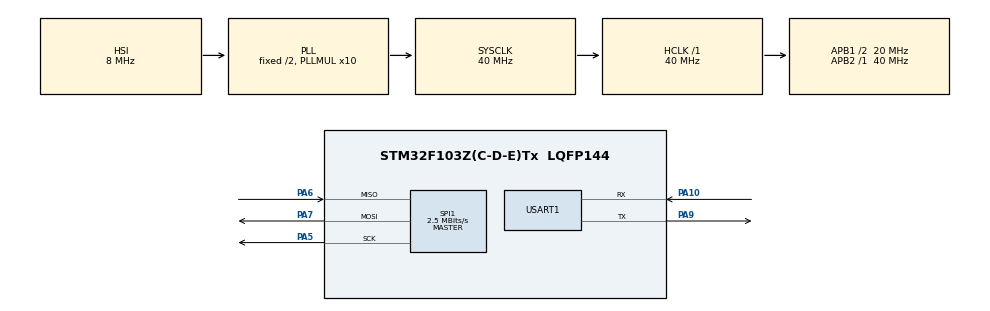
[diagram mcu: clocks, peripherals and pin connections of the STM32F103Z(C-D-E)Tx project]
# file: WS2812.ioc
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Mcu.Family=STM32F1
Mcu.Name=STM32F103Z(C-D-E)Tx
Mcu.Package=LQFP144
NVIC.PriorityGroup=NVIC_PRIORITYGROUP_4
OSC_IN.Mode=HSE-External-Oscillator
OSC_IN.Signal=RCC_OSC_IN
OSC_OUT.Mode=HSE-External-Oscillator
OSC_OUT.Signal=RCC_OSC_OUT
PA10.Mode=Asynchronous
PA10.Signal=USART1_RX
PA13.Mode=Serial_Wire
PA13.Signal=SYS_JTMS-SWDIO
PA14.Mode=Serial_Wire
PA14.Signal=SYS_JTCK-SWCLK
PA5.Mode=Full_Duplex_Master
PA5.Signal=SPI1_SCK
PA6.Mode=Full_Duplex_Master
PA6.Signal=SPI1_MISO
PA7.Mode=Full_Duplex_Master
PA7.Signal=SPI1_MOSI
PA9.Mode=Asynchronous
PA9.Signal=USART1_TX
PC14-OSC32_IN.Mode=LSE-External-Oscillator
PC14-OSC32_IN.Signal=RCC_OSC32_IN
PC15-OSC32_OUT.Mode=LSE-External-Oscillator
PC15-OSC32_OUT.Signal=RCC_OSC32_OUT
ProjectManager.HeapSize=0x200
ProjectManager.StackSize=0x400
ProjectManager.TargetToolchain=MDK-ARM V5.27
RCC.AHBFreq_Value=40000000
RCC.APB1CLKDivider=RCC_HCLK_DIV2
RCC.APB1Freq_Value=20000000
RCC.APB1TimFreq_Value=40000000
RCC.APB2Freq_Value=40000000
RCC.APB2TimFreq_Value=40000000
RCC.HCLKFreq_Value=40000000
RCC.PLLMUL=RCC_PLL_MUL10
RCC.SYSCLKFreq_VALUE=40000000
RCC.SYSCLKSource=RCC_SYSCLKSOURCE_PLLCLK
RCC.USBFreq_Value=40000000
SPI1.BaudRatePrescaler=SPI_BAUDRATEPRESCALER_16
SPI1.CalculateBaudRate=2.5 MBits/s
SPI1.Direction=SPI_DIRECTION_2LINES
SPI1.Mode=SPI_MODE_MASTER
SPI1.VirtualType=VM_MASTER
USART1.VirtualMode=VM_ASYNC
board=custom

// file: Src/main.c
/* USER CODE BEGIN Header */
/**
  ******************************************************************************
  * @file           : main.c
  * @brief          : Main program body
  ******************************************************************************
  * @attention
  *
  * <h2><center>&copy; Copyright (c) 2019 STMicroelectronics.
  * All rights reserved.</center></h2>
  *
  * This software component is licensed by ST under BSD 3-Clause license,
  * the "License"; You may not use this file except in compliance with the
  * License. You may obtain a copy of the License at:
  *                        opensource.org/licenses/BSD-3-Clause
  *
  ******************************************************************************
  */
/* USER CODE END Header */

#include "main.h"
#include "spi.h"
#include "usart.h"
#include "gpio.h"

/* USER CODE BEGIN Includes */
#include "WS2812.h"
/* USER CODE END Includes */

void SystemClock_Config(void);

int main(void)
{

  /* MCU Configuration--------------------------------------------------------*/

  /* Reset of all peripherals, Initializes the Flash interface and the Systick. */
  HAL_Init();

  /* Configure the system clock */
  SystemClock_Config();

  /* Initialize all configured peripherals */
  MX_GPIO_Init();
  MX_SPI1_Init();
  MX_USART1_UART_Init();
  /* USER CODE BEGIN 2 */
	WS2812_Init();
	WS2812_send_data();
	uint8_t R = 0, G = 0, B = 0;
	uint32_t color = 0;
  /* USER CODE END 2 */

  /* Infinite loop */
  /* USER CODE BEGIN WHILE */
  while (1)
  {
//		for(int i = 0; i< 256; i++){
//			G=i;R=i;B=i;
//			WS2812_data9X8bit_data(i,G, R, B);
//		}
//		WS2812_data9X8bit_data(1,255, 0, 0);
//		WS2812_data9X8bit_data(2,0, 255, 0);
//		WS2812_data9X8bit_data(3,255, 255, 255);
		for( int i = 0; i < 1677215; i++){
			WS2812_data9X8bit_data(1,i / 256 / 256 % 256, i / 256 % 256, i%256);
			WS2812_send_data();
			printf("\r\n--%d--",i);
			HAL_Delay(1);
		}

    /* USER CODE END WHILE */

  }
}

void SystemClock_Config(void)
{
  RCC_OscInitTypeDef RCC_OscInitStruct = {0};
  RCC_ClkInitTypeDef RCC_ClkInitStruct = {0};

  /** Initializes the CPU, AHB and APB busses clocks
  */
  RCC_OscInitStruct.OscillatorType = RCC_OSCILLATORTYPE_HSI;
  RCC_OscInitStruct.HSIState = RCC_HSI_ON;
  RCC_OscInitStruct.HSICalibrationValue = RCC_HSICALIBRATION_DEFAULT;
  RCC_OscInitStruct.PLL.PLLState = RCC_PLL_ON;
  RCC_OscInitStruct.PLL.PLLSource = RCC_PLLSOURCE_HSI_DIV2;
  RCC_OscInitStruct.PLL.PLLMUL = RCC_PLL_MUL10;
  if (HAL_RCC_OscConfig(&RCC_OscInitStruct) != HAL_OK)
  {
    Error_Handler();
  }
  /** Initializes the CPU, AHB and APB busses clocks
  */
  RCC_ClkInitStruct.ClockType = RCC_CLOCKTYPE_HCLK|RCC_CLOCKTYPE_SYSCLK
                              |RCC_CLOCKTYPE_PCLK1|RCC_CLOCKTYPE_PCLK2;
  RCC_ClkInitStruct.SYSCLKSource = RCC_SYSCLKSOURCE_PLLCLK;
  RCC_ClkInitStruct.AHBCLKDivider = RCC_SYSCLK_DIV1;
  RCC_ClkInitStruct.APB1CLKDivider = RCC_HCLK_DIV2;
  RCC_ClkInitStruct.APB2CLKDivider = RCC_HCLK_DIV1;

  if (HAL_RCC_ClockConfig(&RCC_ClkInitStruct, FLASH_LATENCY_1) != HAL_OK)
  {
    Error_Handler();
  }
}

void Error_Handler(void)
{
}

/************************ (C) COPYRIGHT STMicroelectronics *****END OF FILE****/
